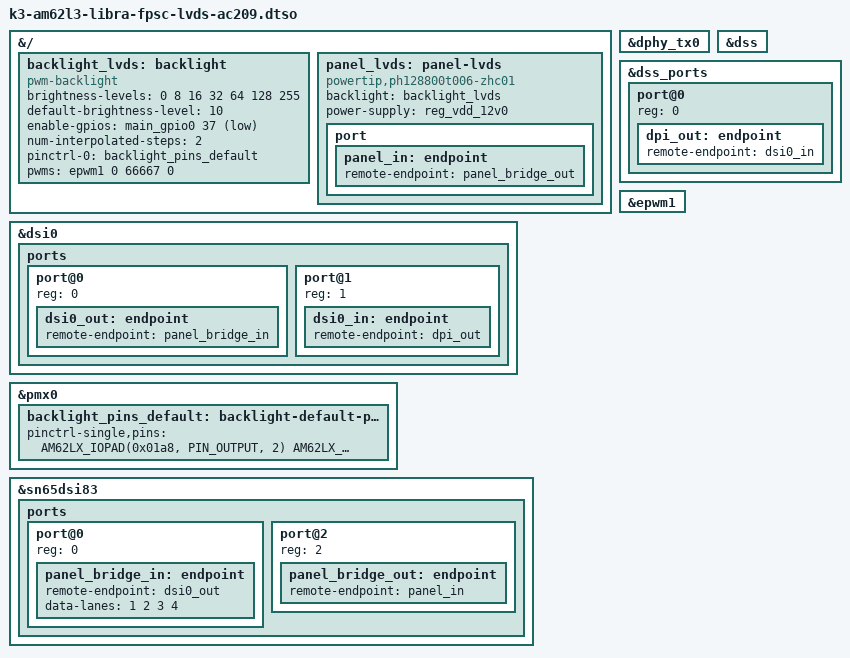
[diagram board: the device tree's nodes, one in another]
// SPDX-License-Identifier: GPL-2.0-only OR MIT
/*
 * Copyright (C) 2025 PHYTEC Messtechnik GmbH
 * Author: Dominik Haller <d.haller@phytec.de>
 *
 */

/dts-v1/;
/plugin/;

#include <dt-bindings/gpio/gpio.h>
#include <dt-bindings/pwm/pwm.h>
#include "k3-pinctrl.h"

&{/} {
	backlight_lvds: backlight {
		compatible = "pwm-backlight";
		brightness-levels = <0 8 16 32 64 128 255>;
		default-brightness-level = <10>;
		enable-gpios = <&main_gpio0 37 GPIO_ACTIVE_LOW>;
		num-interpolated-steps = <2>;
		pinctrl-names = "default";
		pinctrl-0 = <&backlight_pins_default>;
		pwms = <&epwm1 0 66667 0>;
	};

	panel_lvds: panel-lvds {
		compatible = "powertip,ph128800t006-zhc01";
		backlight = <&backlight_lvds>;
		power-supply = <&reg_vdd_12v0>;

		port {
			panel_in: endpoint {
				remote-endpoint = <&panel_bridge_out>;
			};
		};
	};
};

&dphy_tx0 {
	status = "okay";
};

&dsi0 {
	#address-cells = <1>;
	#size-cells = <0>;
	status = "okay";

	ports {
		#address-cells = <1>;
		#size-cells = <0>;

		port@0 {
			reg = <0>;
			dsi0_out: endpoint {
				remote-endpoint = <&panel_bridge_in>;
			};
		};

		port@1 {
			reg = <1>;
			dsi0_in: endpoint {
				remote-endpoint = <&dpi_out>;
			};
		};
	};
};

&dss {
	status = "okay";
};

&dss_ports {
	#address-cells = <1>;
	#size-cells = <0>;

	port@0 {
		reg = <0>;

		dpi_out: endpoint {
			remote-endpoint = <&dsi0_in>;
		};
	};
};

&epwm1 {
	status = "okay";
};

&pmx0 {
	backlight_pins_default: backlight-default-pins {
                pinctrl-single,pins = <
			AM62LX_IOPAD(0x01a8, PIN_OUTPUT, 2) /* (E13) SPI0_CLK.EHRPWM1_A */
			AM62LX_IOPAD(0x00d4, PIN_OUTPUT, 7) /* (N23) GPMC0_WAIT0.GPIO0_37 */
		>;
	};
};

&sn65dsi83 {
	status = "okay";

	ports {
		#address-cells = <1>;
		#size-cells = <0>;

		port@0 {
			reg = <0>;
			panel_bridge_in: endpoint {
				remote-endpoint = <&dsi0_out>;
				data-lanes = <1 2 3 4>;
				};
			};

		port@2 {
			reg = <2>;
			panel_bridge_out: endpoint {
				remote-endpoint = <&panel_in>;
			};
		};
	};
};
